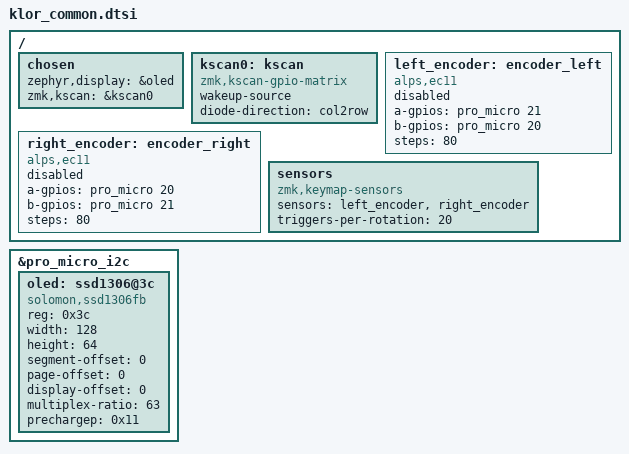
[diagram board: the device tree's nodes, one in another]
/*
 * Copyright (c) 2022 The ZMK Contributors
 * SPDX-License-Identifier: MIT
 */

#include <dt-bindings/zmk/matrix_transform.h>

/ {
    chosen {
        zephyr,display = &oled;
        zmk,kscan = &kscan0;
    };

    kscan0: kscan {
        compatible = "zmk,kscan-gpio-matrix";
        wakeup-source;
        diode-direction = "col2row";
    };

    left_encoder: encoder_left {
        compatible = "alps,ec11";
        a-gpios = <&pro_micro 21 (GPIO_ACTIVE_HIGH | GPIO_PULL_UP)>;
        b-gpios = <&pro_micro 20 (GPIO_ACTIVE_HIGH | GPIO_PULL_UP)>;
        steps = <80>;
        status = "disabled";
    };

    right_encoder: encoder_right {
        compatible = "alps,ec11";
        a-gpios = <&pro_micro 20 (GPIO_ACTIVE_HIGH | GPIO_PULL_UP)>;
        b-gpios = <&pro_micro 21 (GPIO_ACTIVE_HIGH | GPIO_PULL_UP)>;
        steps = <80>;
        status = "disabled";
    };

    sensors: sensors {
        compatible = "zmk,keymap-sensors";
        sensors = <&left_encoder &right_encoder>;
        triggers-per-rotation = <20>;
    };
};

/* Default OLED config for 128x64 (left side) */
&pro_micro_i2c {
    status = "okay";

    oled: ssd1306@3c {
        compatible = "solomon,ssd1306fb";
        reg = <0x3c>;
        width = <128>;
        height = <64>;
        segment-offset = <0>;
        page-offset = <0>;
        display-offset = <0>;
        multiplex-ratio = <63>;
        /* Dimmer: shorter pre-charge phase = lower OLED brightness.
         * Default 0x22 was too bright; 0x11 is noticeably dimmer.
         * Try 0x33 if you actually want it brighter. */
        prechargep = <0x11>;
        /* inversion-on removed — reduces lit-pixel area dramatically,
         * so the display reads dark-background instead of bright background. */
    };
};
